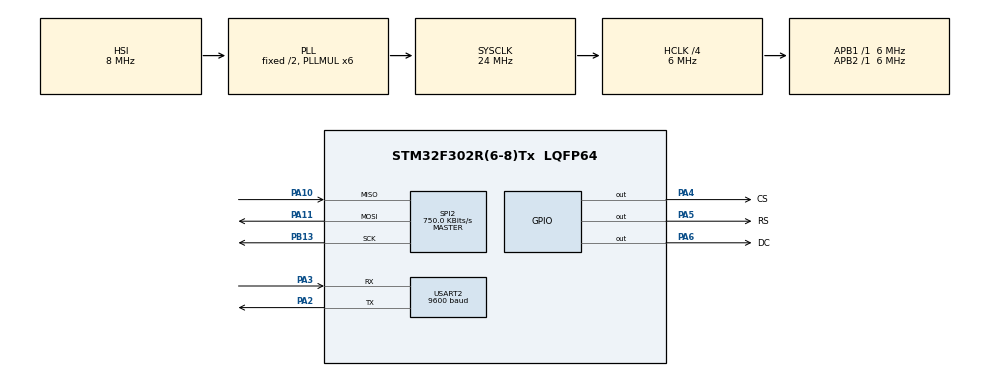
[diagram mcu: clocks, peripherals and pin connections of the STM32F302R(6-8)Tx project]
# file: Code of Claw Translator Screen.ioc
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Mcu.Family=STM32F3
Mcu.Name=STM32F302R(6-8)Tx
Mcu.Package=LQFP64
NVIC.PriorityGroup=NVIC_PRIORITYGROUP_4
PA10.Mode=Full_Duplex_Master
PA10.Signal=SPI2_MISO
PA11.Mode=Full_Duplex_Master
PA11.Signal=SPI2_MOSI
PA2.Mode=Asynchronous
PA2.Signal=USART2_TX
PA3.Mode=Asynchronous
PA3.Signal=USART2_RX
PA4.GPIO_Label=CS
PA4.GPIO_ModeDefaultOutputPP=GPIO_MODE_OUTPUT_PP
PA4.GPIO_PuPd=GPIO_NOPULL
PA4.GPIO_Speed=GPIO_SPEED_FREQ_LOW
PA4.Signal=GPIO_Output
PA5.GPIO_Label=RS
PA5.GPIO_PuPd=GPIO_NOPULL
PA5.GPIO_Speed=GPIO_SPEED_FREQ_LOW
PA5.Signal=GPIO_Output
PA6.GPIO_Label=DC
PA6.GPIO_PuPd=GPIO_NOPULL
PA6.GPIO_Speed=GPIO_SPEED_FREQ_LOW
PA6.Signal=GPIO_Output
PB13.Mode=Full_Duplex_Master
PB13.Signal=SPI2_SCK
ProjectManager.HeapSize=0x200
ProjectManager.StackSize=0x400
ProjectManager.TargetToolchain=STM32CubeIDE
RCC.AHBCLKDivider=RCC_SYSCLK_DIV4
RCC.AHBFreq_Value=6000000
RCC.APB1Freq_Value=6000000
RCC.APB1TimFreq_Value=6000000
RCC.APB2Freq_Value=6000000
RCC.APB2TimFreq_Value=6000000
RCC.CortexFreq_Value=6000000
RCC.HCLKFreq_Value=6000000
RCC.HSE_VALUE=8000000
RCC.HSI_VALUE=8000000
RCC.LSE_VALUE=32768
RCC.PLLMUL=RCC_PLL_MUL6
RCC.SYSCLKFreq_VALUE=24000000
RCC.SYSCLKSourceVirtual=RCC_SYSCLKSOURCE_PLLCLK
RCC.USBFreq_Value=24000000
SPI2.BaudRatePrescaler=SPI_BAUDRATEPRESCALER_8
SPI2.CalculateBaudRate=750.0 KBits/s
SPI2.DataSize=SPI_DATASIZE_8BIT
SPI2.Direction=SPI_DIRECTION_2LINES
SPI2.Mode=SPI_MODE_MASTER
SPI2.NSSPMode=SPI_NSS_PULSE_DISABLE
SPI2.VirtualType=VM_MASTER
USART2.BaudRate=9600
USART2.VirtualMode-Asynchronous=VM_ASYNC
board=custom

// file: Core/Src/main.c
/* USER CODE BEGIN Header */
/**
  ******************************************************************************
  * @file           : main.c
  * @brief          : Main program body
  ******************************************************************************
  * @attention
  *
  * Copyright (c) 2026 STMicroelectronics.
  * All rights reserved.
  *
  * This software is licensed under terms that can be found in the LICENSE file
  * in the root directory of this software component.
  * If no LICENSE file comes with this software, it is provided AS-IS.
  *
  ******************************************************************************
  */
/* USER CODE END Header */
#include "main.h"

/* USER CODE BEGIN Includes */
#include "stdio.h"
#include "stdlib.h"
#include "ILI9341.h"
/* USER CODE END Includes */

SPI_HandleTypeDef hspi2;

UART_HandleTypeDef huart2;

/* USER CODE BEGIN PV */
ILI9341_t ili9341;
char message[50];
/* USER CODE END PV */

void SystemClock_Config(void);
static void MX_GPIO_Init(void);
static void MX_USART2_UART_Init(void);
static void MX_SPI2_Init(void);

int main(void)
{

  /* MCU Configuration--------------------------------------------------------*/

  /* Reset of all peripherals, Initializes the Flash interface and the Systick. */
  HAL_Init();

  /* Configure the system clock */
  SystemClock_Config();

  /* Initialize all configured peripherals */
  MX_GPIO_Init();
  MX_USART2_UART_Init();
  MX_SPI2_Init();
  /* USER CODE BEGIN 2 */
  sprintf (message, "WHY\r\n");
  HAL_UART_Transmit (&huart2, (uint8_t *) message, 50, 100);
  ILI9341_Init(&ili9341, &hspi2, CS_GPIO_Port, CS_Pin, RS_GPIO_Port, RS_Pin, DC_GPIO_Port, DC_Pin);

//  ILI9341_Set_Window_Location (&ili9341, 0x001, 0x0001 + (ROW_SIZE * ili9341.char_size) - 1, 0x0001, 0x0001 + (COL_SIZE * ili9341.char_size) - 1);
//  ILI9341_Fill_Screen (&ili9341, COLOR_WHITE);
//  ILI9341_Write_String(&ili9341, "Hello WORLD.");
  HAL_Delay (1000);
  ILI9341_Write_Character(&ili9341, 'H');
//  ILI9341_Write_Character(&ili9341, 'E');
//  ILI9341_Write_Character(&ili9341, 'l');
//  ILI9341_Write_Character(&ili9341, 'l');
//  ILI9341_Write_Character(&ili9341, 'o');

  /* USER CODE END 2 */

  /* Infinite loop */
  while (1)
  {

  }
}

void SystemClock_Config(void)
{
  RCC_OscInitTypeDef RCC_OscInitStruct = {0};
  RCC_ClkInitTypeDef RCC_ClkInitStruct = {0};

  /** Initializes the RCC Oscillators according to the specified parameters
  * in the RCC_OscInitTypeDef structure.
  */
  RCC_OscInitStruct.OscillatorType = RCC_OSCILLATORTYPE_HSI;
  RCC_OscInitStruct.HSIState = RCC_HSI_ON;
  RCC_OscInitStruct.HSICalibrationValue = RCC_HSICALIBRATION_DEFAULT;
  RCC_OscInitStruct.PLL.PLLState = RCC_PLL_ON;
  RCC_OscInitStruct.PLL.PLLSource = RCC_PLLSOURCE_HSI;
  RCC_OscInitStruct.PLL.PLLMUL = RCC_PLL_MUL6;
  if (HAL_RCC_OscConfig(&RCC_OscInitStruct) != HAL_OK)
  {
    Error_Handler();
  }

  /** Initializes the CPU, AHB and APB buses clocks
  */
  RCC_ClkInitStruct.ClockType = RCC_CLOCKTYPE_HCLK|RCC_CLOCKTYPE_SYSCLK
                              |RCC_CLOCKTYPE_PCLK1|RCC_CLOCKTYPE_PCLK2;
  RCC_ClkInitStruct.SYSCLKSource = RCC_SYSCLKSOURCE_PLLCLK;
  RCC_ClkInitStruct.AHBCLKDivider = RCC_SYSCLK_DIV4;
  RCC_ClkInitStruct.APB1CLKDivider = RCC_HCLK_DIV1;
  RCC_ClkInitStruct.APB2CLKDivider = RCC_HCLK_DIV1;

  if (HAL_RCC_ClockConfig(&RCC_ClkInitStruct, FLASH_LATENCY_0) != HAL_OK)
  {
    Error_Handler();
  }
}

static void MX_SPI2_Init(void)
{

  /* SPI2 parameter configuration*/
  hspi2.Instance = SPI2;
  hspi2.Init.Mode = SPI_MODE_MASTER;
  hspi2.Init.Direction = SPI_DIRECTION_2LINES;
  hspi2.Init.DataSize = SPI_DATASIZE_8BIT;
  hspi2.Init.CLKPolarity = SPI_POLARITY_LOW;
  hspi2.Init.CLKPhase = SPI_PHASE_1EDGE;
  hspi2.Init.NSS = SPI_NSS_SOFT;
  hspi2.Init.BaudRatePrescaler = SPI_BAUDRATEPRESCALER_8;
  hspi2.Init.FirstBit = SPI_FIRSTBIT_MSB;
  hspi2.Init.TIMode = SPI_TIMODE_DISABLE;
  hspi2.Init.CRCCalculation = SPI_CRCCALCULATION_DISABLE;
  hspi2.Init.CRCPolynomial = 7;
  hspi2.Init.CRCLength = SPI_CRC_LENGTH_DATASIZE;
  hspi2.Init.NSSPMode = SPI_NSS_PULSE_DISABLE;
  if (HAL_SPI_Init(&hspi2) != HAL_OK)
  {
    Error_Handler();
  }

}

static void MX_USART2_UART_Init(void)
{

  huart2.Instance = USART2;
  huart2.Init.BaudRate = 9600;
  huart2.Init.WordLength = UART_WORDLENGTH_8B;
  huart2.Init.StopBits = UART_STOPBITS_1;
  huart2.Init.Parity = UART_PARITY_NONE;
  huart2.Init.Mode = UART_MODE_TX_RX;
  huart2.Init.HwFlowCtl = UART_HWCONTROL_NONE;
  huart2.Init.OverSampling = UART_OVERSAMPLING_16;
  huart2.Init.OneBitSampling = UART_ONE_BIT_SAMPLE_DISABLE;
  huart2.AdvancedInit.AdvFeatureInit = UART_ADVFEATURE_NO_INIT;
  if (HAL_UART_Init(&huart2) != HAL_OK)
  {
    Error_Handler();
  }

}

static void MX_GPIO_Init(void)
{
  GPIO_InitTypeDef GPIO_InitStruct = {0};

  /* GPIO Ports Clock Enable */
  __HAL_RCC_GPIOA_CLK_ENABLE();
  __HAL_RCC_GPIOB_CLK_ENABLE();

  /*Configure GPIO pin Output Level */
  HAL_GPIO_WritePin(GPIOA, CS_Pin|RS_Pin|DC_Pin, GPIO_PIN_RESET);

  /*Configure GPIO pins : CS_Pin RS_Pin DC_Pin */
  GPIO_InitStruct.Pin = CS_Pin|RS_Pin|DC_Pin;
  GPIO_InitStruct.Mode = GPIO_MODE_OUTPUT_PP;
  GPIO_InitStruct.Pull = GPIO_NOPULL;
  GPIO_InitStruct.Speed = GPIO_SPEED_FREQ_LOW;
  HAL_GPIO_Init(GPIOA, &GPIO_InitStruct);

}

void Error_Handler(void)
{
  __disable_irq();
  while (1)
  {
  }
}
